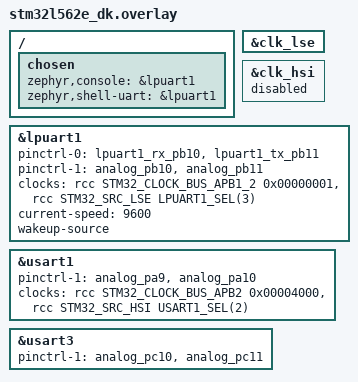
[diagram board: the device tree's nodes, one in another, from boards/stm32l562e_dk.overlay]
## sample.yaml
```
sample:
  name: STM32 Power Management Serial Wakeup
tests:
  sample.boards.stm32.power_mgmt.serial_wakeup:
    tags:
      - UART
      - Wake
      - up
      - power
    harness: console
    harness_config:
      type: multi_line
      regex:
        - "Device is wakeup capable"
        - "Wakeup source enable ok"
        - "Wakeup source enabled"
    integration_platforms:
      - nucleo_wb55rg
    filter: dt_compat_enabled("zephyr,power-state")
    extra_args: "CONFIG_DEBUG=y"
    platform_allow: nucleo_wb55rg
```

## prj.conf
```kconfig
CONFIG_PM=y
CONFIG_PM_DEVICE=y
CONFIG_PM_DEVICE_RUNTIME=n
CONFIG_PM_DEVICE_RUNTIME_EXCLUSIVE=n
CONFIG_SHELL=y

CONFIG_DEBUG=n
```

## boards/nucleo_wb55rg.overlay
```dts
/*
 * Copyright (c) 2022 Linaro Limited
 *
 * SPDX-License-Identifier: Apache-2.0
 */

&clk_hsi {
	status = "okay";
};

&usart1 {
	clocks = <&rcc STM32_CLOCK_BUS_APB2 0x00004000>,
		 <&rcc STM32_SRC_HSI USART1_SEL(2)>;

	wakeup-source;

	pinctrl-1 = <&analog_pb6 &analog_pb7>;
	pinctrl-names = "default", "sleep";
};
```

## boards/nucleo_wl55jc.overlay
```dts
/*
 * Copyright (c) 2022 STMicroelectronics
 *
 * SPDX-License-Identifier: Apache-2.0
 */

&clk_lse {
	status = "okay";
};

/* LPUART1 clock source on LSE : set console at 9600 */
&lpuart1 {
	/delete-property/ clocks;
	clocks = <&rcc STM32_CLOCK_BUS_APB1_2 0x00000001>,
		<&rcc STM32_SRC_LSE LPUART1_SEL(3)>;

	current-speed = <9600>;
	wakeup-source;
	wakeup-line = <28>;
};
```

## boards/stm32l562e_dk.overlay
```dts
/ {
	chosen {
		/* Comment out these lines to use usart1 as console/shell */
		zephyr,console = &lpuart1;
		zephyr,shell-uart = &lpuart1;
	};
};

&clk_lse {
	status = "okay";
};

&clk_hsi {
	/* Comment out this line to use HSI as clk source */
	status = "disabled";
};

&lpuart1 {
	pinctrl-0 = <&lpuart1_rx_pb10 &lpuart1_tx_pb11>;
	pinctrl-1 = <&analog_pb10 &analog_pb11>;
	pinctrl-names = "default", "sleep";

	clocks = <&rcc STM32_CLOCK_BUS_APB1_2 0x00000001>,
		 <&rcc STM32_SRC_LSE LPUART1_SEL(3)>;

	current-speed = <9600>;

	wakeup-source;

	status = "okay";
};

&usart1 {
	pinctrl-1 = <&analog_pa9 &analog_pa10>;
	pinctrl-names = "default", "sleep";

	/* Uncomment out this line to use usart1 as wakeup source */
	/* wakeup-source; */

	clocks = <&rcc STM32_CLOCK_BUS_APB2 0x00004000>,
		 <&rcc STM32_SRC_HSI USART1_SEL(2)>;

	status = "okay";
};

&usart3 {
	status = "okay";
	pinctrl-1 = <&analog_pc10 &analog_pc11>;
	pinctrl-names = "default", "sleep";
};
```

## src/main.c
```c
/*
 * Copyright (c) 2022 Linaro Limited
 *
 * SPDX-License-Identifier: Apache-2.0
 */

#include <zephyr/kernel.h>
#include <zephyr/device.h>
#include <zephyr/pm/device.h>
#include <zephyr/devicetree.h>
#include <zephyr/sys/printk.h>
#include <zephyr/sys/__assert.h>

int main(void)
{
	const struct device *const dev =
		DEVICE_DT_GET(DT_CHOSEN(zephyr_console));

	if (!device_is_ready(dev)) {
		printk("Console device not ready");
		return 0;
	}

#if CONFIG_PM_DEVICE
	/* In PM_DEVICE modes, enable device as a wakeup source will prevent
	 * system to switch it off (clock off, set pins to sleep configuration, ...)
	 * It is not requested in PM mode only since this mode will not
	 */

	bool ret;

	ret = pm_device_wakeup_is_capable(dev);
	if (!ret) {
		printk("Device is not wakeup capable\n");
	} else {
		printk("Device is wakeup capable\n");

		ret = pm_device_wakeup_enable(dev, true);
		if (!ret) {
			printk("Could not enable wakeup source\n");
		} else {
			printk("Wakeup source enable ok\n");
		}

		ret = pm_device_wakeup_is_enabled(dev);
		if (!ret) {
			printk("Wakeup source not enabled\n");
		} else {
			printk("Wakeup source enabled\n");
		}
	}
#endif

	return 0;
}
```
